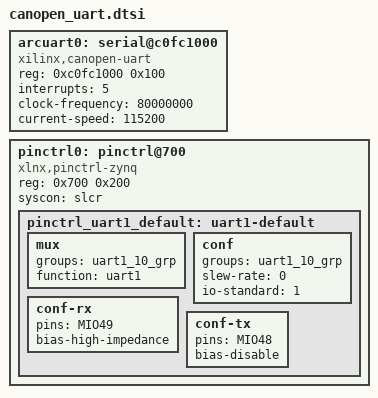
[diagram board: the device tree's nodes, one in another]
/*尚不完善*/
#include "zynq#####"

arcuart0: serial@c0fc1000 { 
	compatible = "xilinx,canopen-uart";
	reg = <0xc0fc1000 0x100>;
	interrupts = <5>;
	clock-frequency = <80000000>;
	current-speed = <115200>;
	status = "okay"; 
	};
	
pinctrl0: pinctrl@700 {
		compatible = "xlnx,pinctrl-zynq";
		reg = <0x700 0x200>;
		syscon = <&slcr>;

		pinctrl_uart1_default: uart1-default {
			mux {
				groups = "uart1_10_grp";
				function = "uart1";
			};

			conf {
				groups = "uart1_10_grp";
				slew-rate = <0>;
				io-standard = <1>;
			};

			conf-rx {
				pins = "MIO49";
				bias-high-impedance;
			};

			conf-tx {
				pins = "MIO48";
				bias-disable;
			};
		};
	};
